# LAN9255ZMX018 register map
Vendor: Microchip
Registers are 32-bit, read-write, reset 0x0 unless marked. A register's access mark holds for its fields unless they carry their own. Addresses are absolute, and some are shared; only a register's first bit layout is shown; [hi:lo] are bit positions; {n}, {i} and the like mark numbered series; 'fields as' and 'values as' point back to an identical list.

## WDT
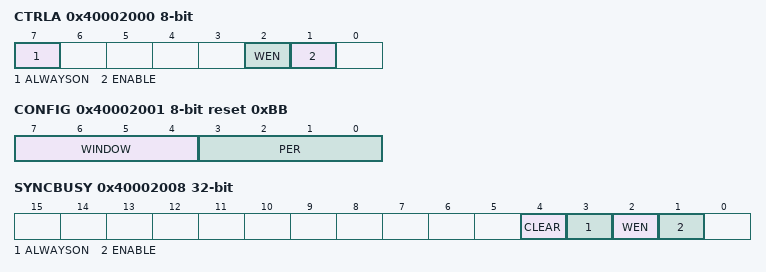
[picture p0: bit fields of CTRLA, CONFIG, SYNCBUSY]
0x40002000 CTRLA 8-bit
  [7] ALWAYSON
  [2] WEN — Watchdog Timer Window Mode Enable
  [1] ENABLE
0x40002001 CONFIG 8-bit reset 0xBB
  [7:4] WINDOW — Window Mode Time-Out Period
    0=CYC8 (8 clock cycles); 1=CYC16 (16 clock cycles); 2=CYC32 (32 clock cycles); 3=CYC64 (64 clock cycles); 4=CYC128 (128 clock cycles); 5=CYC256 (256 clock cycles); 6=CYC512 (512 clock cycles); 7=CYC1024 (1024 clock cycles); 8=CYC2048 (2048 clock cycles); 9=CYC4096 (4096 clock cycles); 10=CYC8192 (8192 clock cycles); 11=CYC16384 (16384 clock cycles)
  [3:0] PER — Time-Out Period
    values as WINDOW
0x40002002 EWCTRL 8-bit reset 0xB
  [3:0] EWOFFSET — Early Warning Interrupt Time Offset
    values as CONFIG.WINDOW
0x40002004 INTENCLR 8-bit
  [0] EW — Early Warning Interrupt Enable
0x40002005 INTENSET 8-bit
  [0] EW — Early Warning Interrupt Enable
0x40002006 INTFLAG 8-bit
  [0] EW — Early Warning
0x40002008 SYNCBUSY ro
  [4] CLEAR — Clear Synchronization Busy
  [3] ALWAYSON — Always-On Synchronization Busy
  [2] WEN — Window Enable Synchronization Busy
  [1] ENABLE — Enable Synchronization Busy
0x4000200C CLEAR 8-bit wo
  [7:0] CLEAR — Watchdog Clear
    165=KEY (Clear Key)

## RTC
0x4000240E DBGCTRL 8-bit
  [0] DBGRUN — Run During Debug
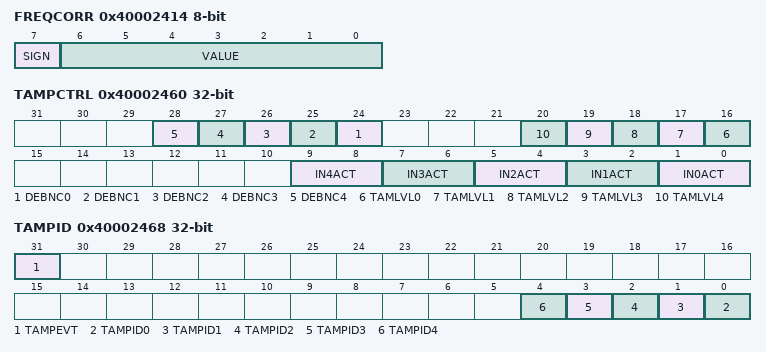
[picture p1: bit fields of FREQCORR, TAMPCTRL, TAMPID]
0x40002414 FREQCORR 8-bit
  [7] SIGN — Correction Sign
  [6:0] VALUE — Correction Value
{0x40002440+4i} GP{i} (i=0..3)
  [31:0] GP — General Purpose
0x40002460 TAMPCTRL
  [n+24] DEBNC{n} (n=0..4) — Debouncer Enable {n}
  [n+16] TAMLVL{n} (n=0..4) — Tamper Level Select {n}
  [2n+1:2n] IN{n}ACT (n=0..4) — Tamper Input {n} Action
    0=OFF (Off (Disabled)); 1=WAKE (Wake without timestamp); 2=CAPTURE (Capture timestamp); 3=ACTL (Compare IN{n} to OUT)
0x40002468 TAMPID
  [31] TAMPEVT — Tamper Event Detected
  [n] TAMPID{n} (n=0..4) — Tamper Input {n} Detected
{0x40002480+4i} BKUP{i} (i=0..7)
  [31:0] BKUP — Backup

## EIC
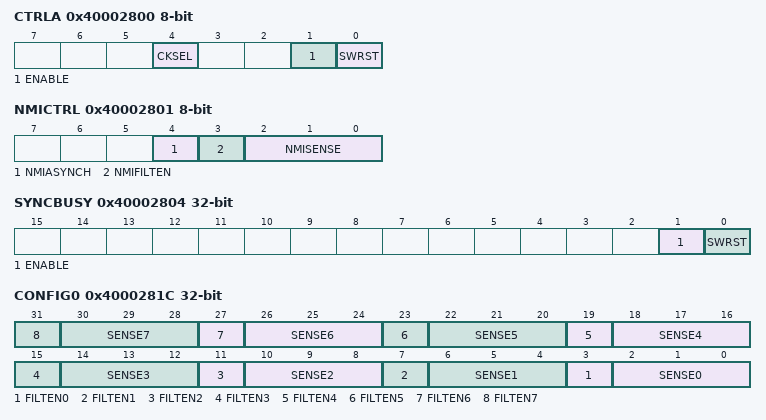
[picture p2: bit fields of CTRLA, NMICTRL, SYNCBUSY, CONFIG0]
0x40002800 CTRLA 8-bit
  [4] CKSEL — Clock Selection
    0=CLK_GCLK (Clocked by GCLK); 1=CLK_ULP32K (Clocked by ULP32K)
  [1] ENABLE
  [0] SWRST — Software Reset
0x40002801 NMICTRL 8-bit
  [4] NMIASYNCH — Asynchronous Edge Detection Mode
    0=SYNC (Edge detection is clock synchronously operated); 1=ASYNC (Edge detection is clock asynchronously operated)
  [3] NMIFILTEN — Non-Maskable Interrupt Filter Enable
  [2:0] NMISENSE — Non-Maskable Interrupt Sense Configuration
    0=NONE (No detection); 1=RISE (Rising-edge detection); 2=FALL (Falling-edge detection); 3=BOTH (Both-edges detection); 4=HIGH (High-level detection); 5=LOW (Low-level detection)
0x40002802 NMIFLAG 16-bit
  [0] NMI — Non-Maskable Interrupt
0x40002804 SYNCBUSY ro
  [1] ENABLE — Enable Synchronization Busy Status
  [0] SWRST — Software Reset Synchronization Busy Status
0x40002808 EVCTRL
  [15:0] EXTINTEO — External Interrupt Event Output Enable
0x4000280C INTENCLR
  [15:0] EXTINT — External Interrupt Enable
0x40002810 INTENSET
  [15:0] EXTINT — External Interrupt Enable
0x40002814 INTFLAG
  [15:0] EXTINT — External Interrupt
0x40002818 ASYNCH
  [15:0] ASYNCH — Asynchronous Edge Detection Mode
    values as NMICTRL.NMIASYNCH
0x4000281C CONFIG0
  [4n+3] FILTEN{n} (n=0..7) — Filter Enable {n}
  [4n+2:4n] SENSE{n} (n=0..7) — Input Sense Configuration {n}
    0=NONE (No detection); 1=RISE (Rising edge detection); 2=FALL (Falling edge detection); 3=BOTH (Both edges detection); 4=HIGH (High level detection); 5=LOW (Low level detection)
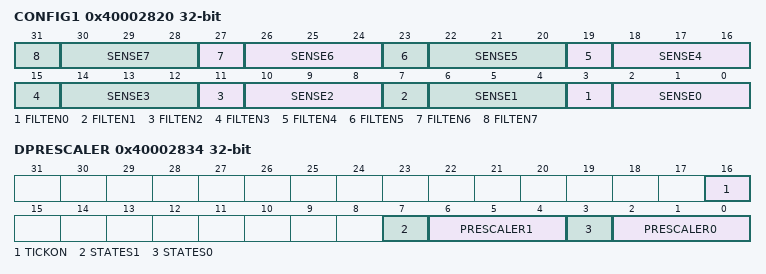
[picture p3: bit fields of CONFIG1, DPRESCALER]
0x40002820 CONFIG1
  fields as CONFIG0
0x40002830 DEBOUNCEN
  [15:0] DEBOUNCEN — Debouncer Enable
0x40002834 DPRESCALER
  [16] TICKON — Pin Sampler frequency selection
    0=CLK_GCLK_EIC (Clocked by GCLK); 1=CLK_LFREQ (Clocked by Low Frequency Clock)
  [7] STATES1 — Debouncer number of states
    0=LFREQ3 (3 low frequency samples); 1=LFREQ7 (7 low frequency samples)
  [6:4] PRESCALER1 — Debouncer Prescaler
    0=DIV2 (EIC clock divided by 2); 1=DIV4 (EIC clock divided by 4); 2=DIV8 (EIC clock divided by 8); 3=DIV16 (EIC clock divided by 16); 4=DIV32 (EIC clock divided by 32); 5=DIV64 (EIC clock divided by 64); 6=DIV128 (EIC clock divided by 128); 7=DIV256 (EIC clock divided by 256)
  [3] STATES0 — Debouncer number of states
    values as STATES1
  [2:0] PRESCALER0 — Debouncer Prescaler
    values as PRESCALER1
0x40002838 PINSTATE ro
  [15:0] PINSTATE
